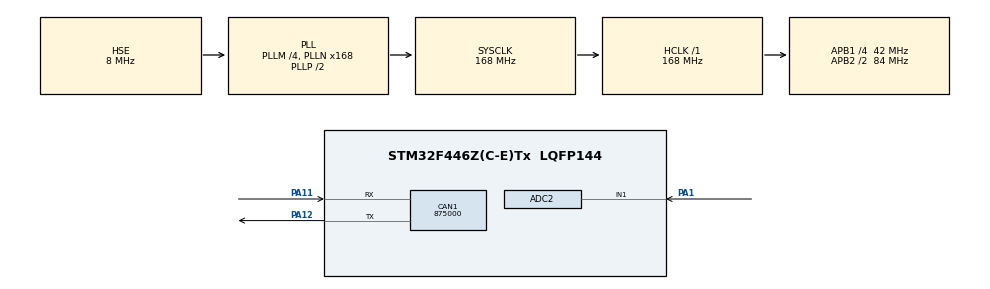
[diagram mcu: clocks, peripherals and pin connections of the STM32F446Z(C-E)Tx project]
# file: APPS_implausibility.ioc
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ADC1.Channel-1\#ChannelRegularConversion=ADC_CHANNEL_1
ADC1.NbrOfConversionFlag=1
ADC1.Rank-1\#ChannelRegularConversion=1
ADC1.SamplingTime-1\#ChannelRegularConversion=ADC_SAMPLETIME_3CYCLES
ADC1.master=1
ADC2.Channel-1\#ChannelRegularConversion=ADC_CHANNEL_1
ADC2.NbrOfConversionFlag=1
ADC2.Rank-1\#ChannelRegularConversion=1
ADC2.SamplingTime-1\#ChannelRegularConversion=ADC_SAMPLETIME_3CYCLES
CAN1.CalculateBaudRate=875000
CAN1.CalculateTimeBit=1142
CAN1.CalculateTimeQuantum=380.95238095238096
Mcu.Family=STM32F4
Mcu.Name=STM32F446Z(C-E)Tx
Mcu.Package=LQFP144
NVIC.PriorityGroup=NVIC_PRIORITYGROUP_4
PA1.Signal=ADCx_IN1
PA11.Mode=CAN_Activate
PA11.Signal=CAN1_RX
PA12.Mode=CAN_Activate
PA12.Signal=CAN1_TX
PH0-OSC_IN.Mode=HSE-External-Oscillator
PH0-OSC_IN.Signal=RCC_OSC_IN
PH1-OSC_OUT.Mode=HSE-External-Oscillator
PH1-OSC_OUT.Signal=RCC_OSC_OUT
ProjectManager.HeapSize=0x200
ProjectManager.StackSize=0x400
ProjectManager.TargetToolchain=STM32CubeIDE
RCC.48MHZClocksFreq_Value=24000000
RCC.AHBFreq_Value=168000000
RCC.APB1CLKDivider=RCC_HCLK_DIV4
RCC.APB1Freq_Value=42000000
RCC.APB1TimFreq_Value=84000000
RCC.APB2CLKDivider=RCC_HCLK_DIV2
RCC.APB2Freq_Value=84000000
RCC.APB2TimFreq_Value=168000000
RCC.CortexFreq_Value=168000000
RCC.HCLKFreq_Value=168000000
RCC.HSE_VALUE=8000000
RCC.HSI_VALUE=16000000
RCC.PLLM=4
RCC.PLLMUL=RCC_PLL_MUL9
RCC.PLLN=168
RCC.PLLQ=7
RCC.PLLSourceVirtual=RCC_PLLSOURCE_HSE
RCC.PRESCALERUSB=RCC_USBCLKSOURCE_PLL_DIV1_5
RCC.SYSCLKFreq_VALUE=168000000
RCC.SYSCLKSource=RCC_SYSCLKSOURCE_PLLCLK
RCC.SYSCLKSourceVirtual=RCC_SYSCLKSOURCE_PLLCLK
RCC.USBFreq_Value=48000000
RCC.VCOOutputFreq_Value=336000000
SH.ADCx_IN1.0=ADC2_IN1,IN1
SH.ADCx_IN1.1=ADC1_IN1,IN1
board=NUCLEO-F446ZE

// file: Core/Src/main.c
/* USER CODE BEGIN Header */
/**
  ******************************************************************************
  * @file           : main.c
  * @brief          : Main program body
  ******************************************************************************
  * @attention
  *
  * Copyright (c) 2023 STMicroelectronics.
  * All rights reserved.
  *
  * This software is licensed under terms that can be found in the LICENSE file
  * in the root directory of this software component.
  * If no LICENSE file comes with this software, it is provided AS-IS.
  *
  ******************************************************************************
  */
/* USER CODE END Header */
#include "main.h"
#include "stm32f4xx.h"

/* USER CODE BEGIN PD */
CAN_TxHeaderTypeDef TxHeader;
uint8_t TxData[8];
uint32_t TxMailbox;
/* USER CODE END PD */

ADC_HandleTypeDef hadc1;
ADC_HandleTypeDef hadc2;

CAN_HandleTypeDef hcan1;

/* USER CODE BEGIN PV */
uint16_t adc_value_1 = 0;
float APPS_1 = 0;
uint16_t adc_value_2 = 0;
float APPS_2 = 0;
/* USER CODE END PV */

void SystemClock_Config(void);
static void MX_GPIO_Init(void);
static void MX_ADC1_Init(void);
static void MX_ADC2_Init(void);
static void MX_CAN1_Init(void);

void CAN1_Init(void)
{
    // CAN peripheral initialization code
    // Set up appropriate baud rate, filters, etc.
    // ...

    // Initialize the CAN message structure
    TxHeader.IDE = CAN_ID_STD;        // Standard CAN ID
    TxHeader.StdId = 0x123;           // Example CAN ID
    TxHeader.RTR = CAN_RTR_DATA;      // Data frame, not a remote frame
    TxHeader.DLC = 8;                 // Data length is 8 bytes
    TxHeader.TransmitGlobalTime = DISABLE;

    // Clear the data payload
    for (uint8_t i = 0; i < 8; i++) {
        TxData[i] = 0x00;
    }
}

// Command to set motor output to zero
void SetMotorOutputZero(void)
{
    // Set the appropriate value in the data payload to command the motor controller
    // In this example, assuming the motor controller expects 0 to indicate zero output
    TxData[0] = 0x00;

    // Send the CAN message
    if (HAL_CAN_AddTxMessage(&hcan1, &TxHeader, TxData, &TxMailbox) != HAL_OK)
    {
        // Error handling if transmission fails
    }
}
int main(void)
{

  /* MCU Configuration--------------------------------------------------------*/

  /* Reset of all peripherals, Initializes the Flash interface and the Systick. */
  HAL_Init();

  /* Configure the system clock */
  SystemClock_Config();

  /* Initialize all configured peripherals */
  MX_GPIO_Init();
  MX_ADC1_Init();
  MX_ADC2_Init();
  MX_CAN1_Init();

  /* Infinite loop */
  /* USER CODE BEGIN WHILE */
  while (1)
  {
	  // Start ADC conversion
	  HAL_ADC_Start(&hadc1);
	  HAL_ADC_Start(&hadc2);

	  // Wait for conversion to complete
	  HAL_ADC_PollForConversion(&hadc1, HAL_MAX_DELAY);
	  HAL_ADC_PollForConversion(&hadc2, HAL_MAX_DELAY);

	  // Read ADC value
	  adc_value_1 = HAL_ADC_GetValue(&hadc1);
	  adc_value_2 = HAL_ADC_GetValue(&hadc2);

	  // Convert ADC value to voltage
	  APPS_1 = adc_value_1 * 3.3 / 4096; // Assuming 12-bit ADC with 3.3V reference voltage
	  APPS_2 = adc_value_2 * 3.3 / 4096; // Assuming 12-bit ADC with 3.3V reference voltage

	  // Perform further processing with the voltage value
	  // For example, you can use it for control or calculations

	  // Stop ADC conversion
	  HAL_ADC_Stop(&hadc1);
	  HAL_ADC_Stop(&hadc2);

	  // Delay or do other tasks as needed
	  HAL_Delay(100);

	  if(APPS_1 != APPS_2)
	  {
		  SetMotorOutputZero();
	  }
    /* USER CODE END WHILE */

  }
}

void SystemClock_Config(void)
{
  RCC_OscInitTypeDef RCC_OscInitStruct = {0};
  RCC_ClkInitTypeDef RCC_ClkInitStruct = {0};

  /** Configure the main internal regulator output voltage
  */
  __HAL_RCC_PWR_CLK_ENABLE();
  __HAL_PWR_VOLTAGESCALING_CONFIG(PWR_REGULATOR_VOLTAGE_SCALE1);

  /** Initializes the RCC Oscillators according to the specified parameters
  * in the RCC_OscInitTypeDef structure.
  */
  RCC_OscInitStruct.OscillatorType = RCC_OSCILLATORTYPE_HSE;
  RCC_OscInitStruct.HSEState = RCC_HSE_ON;
  RCC_OscInitStruct.PLL.PLLState = RCC_PLL_ON;
  RCC_OscInitStruct.PLL.PLLSource = RCC_PLLSOURCE_HSE;
  RCC_OscInitStruct.PLL.PLLM = 4;
  RCC_OscInitStruct.PLL.PLLN = 168;
  RCC_OscInitStruct.PLL.PLLP = RCC_PLLP_DIV2;
  RCC_OscInitStruct.PLL.PLLQ = 7;
  RCC_OscInitStruct.PLL.PLLR = 2;
  if (HAL_RCC_OscConfig(&RCC_OscInitStruct) != HAL_OK)
  {
    Error_Handler();
  }

  /** Initializes the CPU, AHB and APB buses clocks
  */
  RCC_ClkInitStruct.ClockType = RCC_CLOCKTYPE_HCLK|RCC_CLOCKTYPE_SYSCLK
                              |RCC_CLOCKTYPE_PCLK1|RCC_CLOCKTYPE_PCLK2;
  RCC_ClkInitStruct.SYSCLKSource = RCC_SYSCLKSOURCE_PLLCLK;
  RCC_ClkInitStruct.AHBCLKDivider = RCC_SYSCLK_DIV1;
  RCC_ClkInitStruct.APB1CLKDivider = RCC_HCLK_DIV4;
  RCC_ClkInitStruct.APB2CLKDivider = RCC_HCLK_DIV2;

  if (HAL_RCC_ClockConfig(&RCC_ClkInitStruct, FLASH_LATENCY_5) != HAL_OK)
  {
    Error_Handler();
  }
}

static void MX_ADC1_Init(void)
{

  ADC_ChannelConfTypeDef sConfig = {0};

  /** Configure the global features of the ADC (Clock, Resolution, Data Alignment and number of conversion)
  */
  hadc1.Instance = ADC1;
  hadc1.Init.ClockPrescaler = ADC_CLOCK_SYNC_PCLK_DIV4;
  hadc1.Init.Resolution = ADC_RESOLUTION_12B;
  hadc1.Init.ScanConvMode = DISABLE;
  hadc1.Init.ContinuousConvMode = DISABLE;
  hadc1.Init.DiscontinuousConvMode = DISABLE;
  hadc1.Init.ExternalTrigConvEdge = ADC_EXTERNALTRIGCONVEDGE_NONE;
  hadc1.Init.ExternalTrigConv = ADC_SOFTWARE_START;
  hadc1.Init.DataAlign = ADC_DATAALIGN_RIGHT;
  hadc1.Init.NbrOfConversion = 1;
  hadc1.Init.DMAContinuousRequests = DISABLE;
  hadc1.Init.EOCSelection = ADC_EOC_SINGLE_CONV;
  if (HAL_ADC_Init(&hadc1) != HAL_OK)
  {
    Error_Handler();
  }

  /** Configure for the selected ADC regular channel its corresponding rank in the sequencer and its sample time.
  */
  sConfig.Channel = ADC_CHANNEL_1;
  sConfig.Rank = 1;
  sConfig.SamplingTime = ADC_SAMPLETIME_3CYCLES;
  if (HAL_ADC_ConfigChannel(&hadc1, &sConfig) != HAL_OK)
  {
    Error_Handler();
  }

}

static void MX_ADC2_Init(void)
{

  ADC_ChannelConfTypeDef sConfig = {0};

  /** Configure the global features of the ADC (Clock, Resolution, Data Alignment and number of conversion)
  */
  hadc2.Instance = ADC2;
  hadc2.Init.ClockPrescaler = ADC_CLOCK_SYNC_PCLK_DIV4;
  hadc2.Init.Resolution = ADC_RESOLUTION_12B;
  hadc2.Init.ScanConvMode = DISABLE;
  hadc2.Init.ContinuousConvMode = DISABLE;
  hadc2.Init.DiscontinuousConvMode = DISABLE;
  hadc2.Init.ExternalTrigConvEdge = ADC_EXTERNALTRIGCONVEDGE_NONE;
  hadc2.Init.ExternalTrigConv = ADC_SOFTWARE_START;
  hadc2.Init.DataAlign = ADC_DATAALIGN_RIGHT;
  hadc2.Init.NbrOfConversion = 1;
  hadc2.Init.DMAContinuousRequests = DISABLE;
  hadc2.Init.EOCSelection = ADC_EOC_SINGLE_CONV;
  if (HAL_ADC_Init(&hadc2) != HAL_OK)
  {
    Error_Handler();
  }

  /** Configure for the selected ADC regular channel its corresponding rank in the sequencer and its sample time.
  */
  sConfig.Channel = ADC_CHANNEL_1;
  sConfig.Rank = 1;
  sConfig.SamplingTime = ADC_SAMPLETIME_3CYCLES;
  if (HAL_ADC_ConfigChannel(&hadc2, &sConfig) != HAL_OK)
  {
    Error_Handler();
  }

}

static void MX_CAN1_Init(void)
{

  hcan1.Instance = CAN1;
  hcan1.Init.Prescaler = 16;
  hcan1.Init.Mode = CAN_MODE_NORMAL;
  hcan1.Init.SyncJumpWidth = CAN_SJW_1TQ;
  hcan1.Init.TimeSeg1 = CAN_BS1_1TQ;
  hcan1.Init.TimeSeg2 = CAN_BS2_1TQ;
  hcan1.Init.TimeTriggeredMode = DISABLE;
  hcan1.Init.AutoBusOff = DISABLE;
  hcan1.Init.AutoWakeUp = DISABLE;
  hcan1.Init.AutoRetransmission = DISABLE;
  hcan1.Init.ReceiveFifoLocked = DISABLE;
  hcan1.Init.TransmitFifoPriority = DISABLE;
  if (HAL_CAN_Init(&hcan1) != HAL_OK)
  {
    Error_Handler();
  }

}

static void MX_GPIO_Init(void)
{

  /* GPIO Ports Clock Enable */
  __HAL_RCC_GPIOH_CLK_ENABLE();
  __HAL_RCC_GPIOA_CLK_ENABLE();

}

void Error_Handler(void)
{
  __disable_irq();
  while (1)
  {
  }
}
